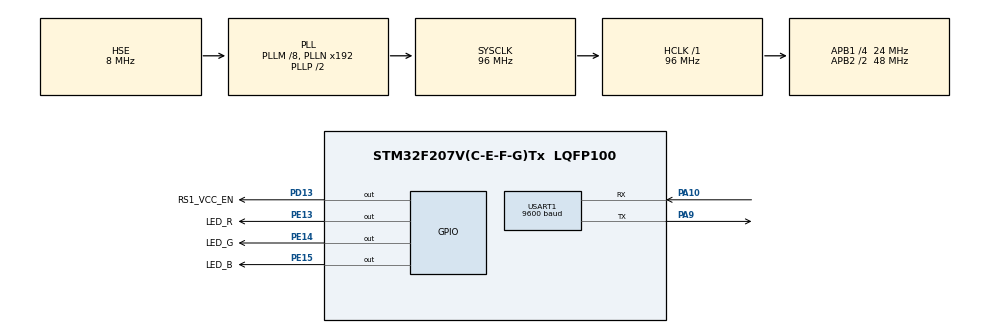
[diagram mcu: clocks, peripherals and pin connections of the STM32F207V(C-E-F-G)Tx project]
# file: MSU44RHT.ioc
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Mcu.Family=STM32F2
Mcu.Name=STM32F207V(C-E-F-G)Tx
Mcu.Package=LQFP100
NVIC.PriorityGroup=NVIC_PRIORITYGROUP_4
NVIC.USART1_IRQn=true\:0\:0\:false\:false\:true\:true\:true
PA10.Mode=Asynchronous
PA10.Signal=USART1_RX
PA13.Mode=Serial_Wire
PA13.Signal=SYS_JTMS-SWDIO
PA14.Mode=Serial_Wire
PA14.Signal=SYS_JTCK-SWCLK
PA9.Mode=Asynchronous
PA9.Signal=USART1_TX
PC14-OSC32_IN.Mode=LSE-External-Oscillator
PC14-OSC32_IN.Signal=RCC_OSC32_IN
PC15-OSC32_OUT.Mode=LSE-External-Oscillator
PC15-OSC32_OUT.Signal=RCC_OSC32_OUT
PD13.GPIO_Label=RS1_VCC_EN
PD13.Signal=GPIO_Output
PE13.GPIO_Label=LED_R
PE13.Signal=GPIO_Output
PE14.GPIO_Label=LED_G
PE14.Signal=GPIO_Output
PE15.GPIO_Label=LED_B
PE15.Signal=GPIO_Output
PH0-OSC_IN.Mode=HSE-External-Oscillator
PH0-OSC_IN.Signal=RCC_OSC_IN
PH1-OSC_OUT.Mode=HSE-External-Oscillator
PH1-OSC_OUT.Signal=RCC_OSC_OUT
ProjectManager.HeapSize=0x200
ProjectManager.StackSize=0x400
ProjectManager.TargetToolchain=EWARM V8.32
RCC.48MHZClocksFreq_Value=48000000
RCC.AHBFreq_Value=96000000
RCC.APB1CLKDivider=RCC_HCLK_DIV4
RCC.APB1Freq_Value=24000000
RCC.APB1TimFreq_Value=48000000
RCC.APB2CLKDivider=RCC_HCLK_DIV2
RCC.APB2Freq_Value=48000000
RCC.APB2TimFreq_Value=96000000
RCC.CortexFreq_Value=12000000
RCC.Cortex_Div=SYSTICK_CLKSOURCE_HCLK_DIV8
RCC.HCLKFreq_Value=96000000
RCC.HSE_VALUE=8000000
RCC.HSI_VALUE=16000000
RCC.PLLM=8
RCC.PLLSourceVirtual=RCC_PLLSOURCE_HSE
RCC.SYSCLKFreq_VALUE=96000000
RCC.SYSCLKSource=RCC_SYSCLKSOURCE_PLLCLK
RCC.VCOOutputFreq_Value=192000000
USART1.BaudRate=9600
USART1.StopBits=STOPBITS_2
USART1.VirtualMode=VM_ASYNC
board=custom

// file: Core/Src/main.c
/* USER CODE BEGIN Header */
/**
  ******************************************************************************
  * @file           : main.c
  * @brief          : Main program body
  ******************************************************************************
  * @attention
  *
  * Copyright (c) 2022 STMicroelectronics.
  * All rights reserved.
  *
  * This software is licensed under terms that can be found in the LICENSE file
  * in the root directory of this software component.
  * If no LICENSE file comes with this software, it is provided AS-IS.
  *
  ******************************************************************************
  */
/* USER CODE END Header */
#include "main.h"

UART_HandleTypeDef huart1;

void SystemClock_Config(void);
static void MX_GPIO_Init(void);
static void MX_USART1_UART_Init(void);

int main(void)
{
  /* USER CODE BEGIN 1 */
  uint8_t msg_trans[8] = {0x01, 0x04, 0x00, 0x1E, 0x00, 0x04, 0x91, 0xCF};
  uint8_t msg_rec[10];
  /* USER CODE END 1 */

  /* MCU Configuration--------------------------------------------------------*/

  /* Reset of all peripherals, Initializes the Flash interface and the Systick. */
  HAL_Init();

  /* Configure the system clock */
  SystemClock_Config();

  /* Initialize all configured peripherals */
  MX_GPIO_Init();
  MX_USART1_UART_Init();

  /* Infinite loop */
  while (1)
  {

//    LED_set_color(PURPLE);
//    HAL_Delay(2000);
//    float a = Read_Temp();
//    float b = Read_Humidity();
//    Change_Slave_Address(0x01);
    //RS_transmit_mode();
    //HAL_UART_Transmit(&_MSU, msg_trans, sizeof(msg_trans), 1000);
    //RS_receive_mode();
    //HAL_UART_Receive(&_MSU, msg_rec, sizeof(msg_rec), 1000);
//      Read_Reg(0x04, 0x00, 0x1E, 0x04, msg_rec, sizeof(msg_rec));
      Read_Reg(0x04, 0x00, 0x00, 0x04, msg_rec, sizeof(msg_rec));
      printf("%d %d\n", msg_rec[0], msg_rec[1]);

  }
}

void SystemClock_Config(void)
{
  RCC_OscInitTypeDef RCC_OscInitStruct = {0};
  RCC_ClkInitTypeDef RCC_ClkInitStruct = {0};

  /** Initializes the RCC Oscillators according to the specified parameters
  * in the RCC_OscInitTypeDef structure.
  */
  RCC_OscInitStruct.OscillatorType = RCC_OSCILLATORTYPE_HSE;
  RCC_OscInitStruct.HSEState = RCC_HSE_ON;
  RCC_OscInitStruct.PLL.PLLState = RCC_PLL_ON;
  RCC_OscInitStruct.PLL.PLLSource = RCC_PLLSOURCE_HSE;
  RCC_OscInitStruct.PLL.PLLM = 8;
  RCC_OscInitStruct.PLL.PLLN = 192;
  RCC_OscInitStruct.PLL.PLLP = RCC_PLLP_DIV2;
  RCC_OscInitStruct.PLL.PLLQ = 4;
  if (HAL_RCC_OscConfig(&RCC_OscInitStruct) != HAL_OK)
  {
    Error_Handler();
  }
  /** Initializes the CPU, AHB and APB buses clocks
  */
  RCC_ClkInitStruct.ClockType = RCC_CLOCKTYPE_HCLK|RCC_CLOCKTYPE_SYSCLK
                              |RCC_CLOCKTYPE_PCLK1|RCC_CLOCKTYPE_PCLK2;
  RCC_ClkInitStruct.SYSCLKSource = RCC_SYSCLKSOURCE_PLLCLK;
  RCC_ClkInitStruct.AHBCLKDivider = RCC_SYSCLK_DIV1;
  RCC_ClkInitStruct.APB1CLKDivider = RCC_HCLK_DIV4;
  RCC_ClkInitStruct.APB2CLKDivider = RCC_HCLK_DIV2;

  if (HAL_RCC_ClockConfig(&RCC_ClkInitStruct, FLASH_LATENCY_3) != HAL_OK)
  {
    Error_Handler();
  }
}

static void MX_USART1_UART_Init(void)
{

  huart1.Instance = USART1;
  huart1.Init.BaudRate = 9600;                  // change
  huart1.Init.WordLength = UART_WORDLENGTH_8B;
  huart1.Init.StopBits = UART_STOPBITS_2;       // change
  huart1.Init.Parity = UART_PARITY_NONE;        // change
  huart1.Init.Mode = UART_MODE_TX_RX;
  huart1.Init.HwFlowCtl = UART_HWCONTROL_NONE;
  huart1.Init.OverSampling = UART_OVERSAMPLING_16;
  if (HAL_UART_Init(&huart1) != HAL_OK)
  {
    Error_Handler();
  }

}

static void MX_GPIO_Init(void)
{
  GPIO_InitTypeDef GPIO_InitStruct = {0};

  /* GPIO Ports Clock Enable */
  __HAL_RCC_GPIOC_CLK_ENABLE();
  __HAL_RCC_GPIOH_CLK_ENABLE();
  __HAL_RCC_GPIOE_CLK_ENABLE();
  __HAL_RCC_GPIOD_CLK_ENABLE();
  __HAL_RCC_GPIOA_CLK_ENABLE();

  /*Configure GPIO pin Output Level */
  HAL_GPIO_WritePin(GPIOE, LED_R_Pin|LED_G_Pin|LED_B_Pin, GPIO_PIN_RESET);

  /*Configure GPIO pin Output Level */
  HAL_GPIO_WritePin(RS1_VCC_EN_GPIO_Port, RS1_VCC_EN_Pin, GPIO_PIN_RESET);

  /*Configure GPIO pins : LED_R_Pin LED_G_Pin LED_B_Pin */
  GPIO_InitStruct.Pin = LED_R_Pin|LED_G_Pin|LED_B_Pin;
  GPIO_InitStruct.Mode = GPIO_MODE_OUTPUT_PP;
  GPIO_InitStruct.Pull = GPIO_NOPULL;
  GPIO_InitStruct.Speed = GPIO_SPEED_FREQ_LOW;
  HAL_GPIO_Init(GPIOE, &GPIO_InitStruct);

  /*Configure GPIO pin : RS1_VCC_EN_Pin */
  GPIO_InitStruct.Pin = RS1_VCC_EN_Pin;
  GPIO_InitStruct.Mode = GPIO_MODE_OUTPUT_PP;
  GPIO_InitStruct.Pull = GPIO_NOPULL;
  GPIO_InitStruct.Speed = GPIO_SPEED_FREQ_LOW;
  HAL_GPIO_Init(RS1_VCC_EN_GPIO_Port, &GPIO_InitStruct);

}

void Error_Handler(void)
{
  __disable_irq();
  while (1)
  {
  }
}
